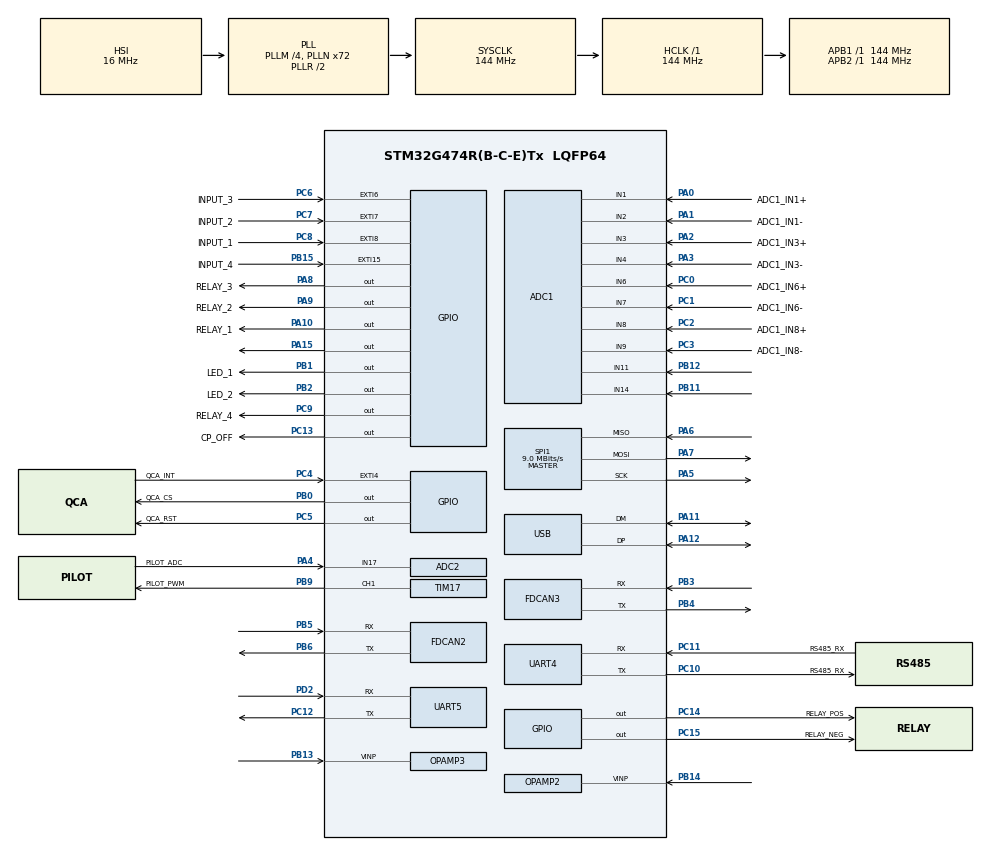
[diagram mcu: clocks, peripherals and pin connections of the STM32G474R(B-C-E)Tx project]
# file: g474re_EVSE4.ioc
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ADC1.Channel-26\#ChannelRegularConversion=ADC_CHANNEL_1
ADC1.Channel-27\#ChannelRegularConversion=ADC_CHANNEL_2
ADC1.Channel-28\#ChannelRegularConversion=ADC_CHANNEL_3
ADC1.Channel-29\#ChannelRegularConversion=ADC_CHANNEL_4
ADC1.Channel-30\#ChannelRegularConversion=ADC_CHANNEL_6
ADC1.Channel-31\#ChannelRegularConversion=ADC_CHANNEL_7
ADC1.Channel-32\#ChannelRegularConversion=ADC_CHANNEL_8
ADC1.Channel-33\#ChannelRegularConversion=ADC_CHANNEL_9
ADC1.Channel-34\#ChannelRegularConversion=ADC_CHANNEL_TEMPSENSOR_ADC1
ADC1.Channel-35\#ChannelRegularConversion=ADC_CHANNEL_VREFINT
ADC1.Channel-36\#ChannelRegularConversion=ADC_CHANNEL_TEMPSENSOR_ADC1
ADC1.Channel-37\#ChannelRegularConversion=ADC_CHANNEL_11
ADC1.Channel-38\#ChannelRegularConversion=ADC_CHANNEL_14
ADC1.ClockPrescaler=ADC_CLOCK_ASYNC_DIV256
ADC1.ContinuousConvMode=ENABLE
ADC1.DMAContinuousRequests=DISABLE
ADC1.EOCSelection=ADC_EOC_SEQ_CONV
ADC1.EnableRegularConversion=ENABLE
ADC1.NbrOfConversion=13
ADC1.NbrOfConversionFlag=1
ADC1.OffsetNumber-26\#ChannelRegularConversion=ADC_OFFSET_NONE
ADC1.OffsetNumber-27\#ChannelRegularConversion=ADC_OFFSET_NONE
ADC1.OffsetNumber-28\#ChannelRegularConversion=ADC_OFFSET_NONE
ADC1.OffsetNumber-29\#ChannelRegularConversion=ADC_OFFSET_NONE
ADC1.OffsetNumber-30\#ChannelRegularConversion=ADC_OFFSET_NONE
ADC1.OffsetNumber-31\#ChannelRegularConversion=ADC_OFFSET_NONE
ADC1.OffsetNumber-32\#ChannelRegularConversion=ADC_OFFSET_NONE
ADC1.OffsetNumber-33\#ChannelRegularConversion=ADC_OFFSET_NONE
ADC1.OffsetNumber-34\#ChannelRegularConversion=ADC_OFFSET_NONE
ADC1.OffsetNumber-35\#ChannelRegularConversion=ADC_OFFSET_NONE
ADC1.OffsetNumber-36\#ChannelRegularConversion=ADC_OFFSET_NONE
ADC1.OffsetNumber-37\#ChannelRegularConversion=ADC_OFFSET_NONE
ADC1.OffsetNumber-38\#ChannelRegularConversion=ADC_OFFSET_NONE
ADC1.Overrun=ADC_OVR_DATA_PRESERVED
ADC1.OversamplingMode=DISABLE
ADC1.Rank-26\#ChannelRegularConversion=1
ADC1.Rank-27\#ChannelRegularConversion=2
ADC1.Rank-28\#ChannelRegularConversion=3
ADC1.Rank-29\#ChannelRegularConversion=4
ADC1.Rank-30\#ChannelRegularConversion=5
ADC1.Rank-31\#ChannelRegularConversion=6
ADC1.Rank-32\#ChannelRegularConversion=7
ADC1.Rank-33\#ChannelRegularConversion=8
ADC1.Rank-34\#ChannelRegularConversion=9
ADC1.Rank-35\#ChannelRegularConversion=10
ADC1.Rank-36\#ChannelRegularConversion=11
ADC1.Rank-37\#ChannelRegularConversion=12
ADC1.Rank-38\#ChannelRegularConversion=13
ADC1.SamplingTime-26\#ChannelRegularConversion=ADC_SAMPLETIME_640CYCLES_5
ADC1.SamplingTime-27\#ChannelRegularConversion=ADC_SAMPLETIME_640CYCLES_5
ADC1.SamplingTime-28\#ChannelRegularConversion=ADC_SAMPLETIME_640CYCLES_5
ADC1.SamplingTime-29\#ChannelRegularConversion=ADC_SAMPLETIME_640CYCLES_5
ADC1.SamplingTime-30\#ChannelRegularConversion=ADC_SAMPLETIME_640CYCLES_5
ADC1.SamplingTime-31\#ChannelRegularConversion=ADC_SAMPLETIME_640CYCLES_5
ADC1.SamplingTime-32\#ChannelRegularConversion=ADC_SAMPLETIME_640CYCLES_5
ADC1.SamplingTime-33\#ChannelRegularConversion=ADC_SAMPLETIME_640CYCLES_5
ADC1.SamplingTime-34\#ChannelRegularConversion=ADC_SAMPLETIME_640CYCLES_5
ADC1.SamplingTime-35\#ChannelRegularConversion=ADC_SAMPLETIME_640CYCLES_5
ADC1.SamplingTime-36\#ChannelRegularConversion=ADC_SAMPLETIME_640CYCLES_5
ADC1.SamplingTime-37\#ChannelRegularConversion=ADC_SAMPLETIME_640CYCLES_5
ADC1.SamplingTime-38\#ChannelRegularConversion=ADC_SAMPLETIME_640CYCLES_5
ADC1.master=1
ADC2.Channel-0\#ChannelRegularConversion=ADC_CHANNEL_17
ADC2.Channel-1\#ChannelRegularConversion=ADC_CHANNEL_VOPAMP2
ADC2.Channel-2\#ChannelRegularConversion=ADC_CHANNEL_VOPAMP3_ADC2
ADC2.ClockPrescaler=ADC_CLOCK_ASYNC_DIV256
ADC2.ContinuousConvMode=ENABLE
ADC2.EOCSelection=ADC_EOC_SEQ_CONV
ADC2.NbrOfConversion=3
ADC2.NbrOfConversionFlag=1
ADC2.OffsetNumber-0\#ChannelRegularConversion=ADC_OFFSET_NONE
ADC2.OffsetNumber-1\#ChannelRegularConversion=ADC_OFFSET_NONE
ADC2.OffsetNumber-2\#ChannelRegularConversion=ADC_OFFSET_NONE
ADC2.OversamplingMode=DISABLE
ADC2.Rank-0\#ChannelRegularConversion=1
ADC2.Rank-1\#ChannelRegularConversion=2
ADC2.Rank-2\#ChannelRegularConversion=3
ADC2.SamplingTime-0\#ChannelRegularConversion=ADC_SAMPLETIME_640CYCLES_5
ADC2.SamplingTime-1\#ChannelRegularConversion=ADC_SAMPLETIME_640CYCLES_5
ADC2.SamplingTime-2\#ChannelRegularConversion=ADC_SAMPLETIME_640CYCLES_5
Dma.ADC1.0.Direction=DMA_PERIPH_TO_MEMORY
Dma.ADC1.0.EventEnable=DISABLE
Dma.ADC1.0.Instance=DMA1_Channel1
Dma.ADC1.0.MemDataAlignment=DMA_MDATAALIGN_WORD
Dma.ADC1.0.MemInc=DMA_MINC_ENABLE
Dma.ADC1.0.Mode=DMA_CIRCULAR
Dma.ADC1.0.PeriphDataAlignment=DMA_PDATAALIGN_WORD
Dma.ADC1.0.PeriphInc=DMA_PINC_DISABLE
Dma.ADC1.0.Polarity=HAL_DMAMUX_REQ_GEN_RISING
Dma.ADC1.0.Priority=DMA_PRIORITY_LOW
Dma.ADC1.0.RequestNumber=1
Dma.ADC1.0.SignalID=NONE
Dma.ADC1.0.SyncEnable=DISABLE
Dma.ADC1.0.SyncPolarity=HAL_DMAMUX_SYNC_NO_EVENT
Dma.ADC1.0.SyncRequestNumber=1
Dma.ADC1.0.SyncSignalID=NONE
Dma.ADC2.1.Direction=DMA_PERIPH_TO_MEMORY
Dma.ADC2.1.EventEnable=DISABLE
Dma.ADC2.1.Instance=DMA1_Channel2
Dma.ADC2.1.MemDataAlignment=DMA_MDATAALIGN_WORD
Dma.ADC2.1.MemInc=DMA_MINC_ENABLE
Dma.ADC2.1.Mode=DMA_CIRCULAR
Dma.ADC2.1.PeriphDataAlignment=DMA_PDATAALIGN_WORD
Dma.ADC2.1.PeriphInc=DMA_PINC_DISABLE
Dma.ADC2.1.Polarity=HAL_DMAMUX_REQ_GEN_RISING
Dma.ADC2.1.Priority=DMA_PRIORITY_LOW
Dma.ADC2.1.RequestNumber=1
Dma.ADC2.1.SignalID=NONE
Dma.ADC2.1.SyncEnable=DISABLE
Dma.ADC2.1.SyncPolarity=HAL_DMAMUX_SYNC_NO_EVENT
Dma.ADC2.1.SyncRequestNumber=1
Dma.ADC2.1.SyncSignalID=NONE
Dma.Request0=ADC1
Dma.Request1=ADC2
Dma.Request2=UART5_RX
Dma.Request3=UART5_TX
Dma.UART5_RX.2.Direction=DMA_PERIPH_TO_MEMORY
Dma.UART5_RX.2.EventEnable=DISABLE
Dma.UART5_RX.2.Instance=DMA1_Channel3
Dma.UART5_RX.2.MemDataAlignment=DMA_MDATAALIGN_BYTE
Dma.UART5_RX.2.MemInc=DMA_MINC_ENABLE
Dma.UART5_RX.2.Mode=DMA_CIRCULAR
Dma.UART5_RX.2.PeriphDataAlignment=DMA_PDATAALIGN_BYTE
Dma.UART5_RX.2.PeriphInc=DMA_PINC_DISABLE
Dma.UART5_RX.2.Polarity=HAL_DMAMUX_REQ_GEN_RISING
Dma.UART5_RX.2.Priority=DMA_PRIORITY_LOW
Dma.UART5_RX.2.RequestNumber=1
Dma.UART5_RX.2.SignalID=NONE
Dma.UART5_RX.2.SyncEnable=DISABLE
Dma.UART5_RX.2.SyncPolarity=HAL_DMAMUX_SYNC_NO_EVENT
Dma.UART5_RX.2.SyncRequestNumber=1
Dma.UART5_RX.2.SyncSignalID=NONE
Dma.UART5_TX.3.Direction=DMA_MEMORY_TO_PERIPH
Dma.UART5_TX.3.EventEnable=DISABLE
Dma.UART5_TX.3.Instance=DMA1_Channel4
Dma.UART5_TX.3.MemDataAlignment=DMA_MDATAALIGN_BYTE
Dma.UART5_TX.3.MemInc=DMA_MINC_ENABLE
Dma.UART5_TX.3.Mode=DMA_NORMAL
Dma.UART5_TX.3.PeriphDataAlignment=DMA_PDATAALIGN_BYTE
Dma.UART5_TX.3.PeriphInc=DMA_PINC_DISABLE
Dma.UART5_TX.3.Polarity=HAL_DMAMUX_REQ_GEN_RISING
Dma.UART5_TX.3.Priority=DMA_PRIORITY_LOW
Dma.UART5_TX.3.RequestNumber=1
Dma.UART5_TX.3.SignalID=NONE
Dma.UART5_TX.3.SyncEnable=DISABLE
Dma.UART5_TX.3.SyncPolarity=HAL_DMAMUX_SYNC_NO_EVENT
Dma.UART5_TX.3.SyncRequestNumber=1
Dma.UART5_TX.3.SyncSignalID=NONE
FDCAN2.AutoRetransmission=DISABLE
FDCAN2.CalculateBaudRateNominal=125000
FDCAN2.CalculateTimeBitNominal=8000
FDCAN2.CalculateTimeQuantumNominal=125.0
FDCAN2.DataSyncJumpWidth=4
FDCAN2.DataTimeSeg1=5
FDCAN2.DataTimeSeg2=4
FDCAN2.ExtFiltersNbr=1
FDCAN2.FrameFormat=FDCAN_FRAME_FD_BRS
FDCAN2.NominalPrescaler=6
FDCAN2.NominalSyncJumpWidth=16
FDCAN2.NominalTimeSeg1=28
FDCAN2.NominalTimeSeg2=35
FDCAN2.ProtocolException=DISABLE
FDCAN2.StdFiltersNbr=1
FDCAN2.TransmitPause=ENABLE
FDCAN3.AutoRetransmission=DISABLE
FDCAN3.CalculateBaudRateNominal=125000
FDCAN3.CalculateTimeBitNominal=8000
FDCAN3.CalculateTimeQuantumNominal=125.0
FDCAN3.DataSyncJumpWidth=4
FDCAN3.DataTimeSeg2=4
FDCAN3.ExtFiltersNbr=1
FDCAN3.FrameFormat=FDCAN_FRAME_FD_BRS
FDCAN3.NominalPrescaler=6
FDCAN3.NominalSyncJumpWidth=16
FDCAN3.NominalTimeSeg1=28
FDCAN3.NominalTimeSeg2=35
FDCAN3.StdFiltersNbr=1
FDCAN3.TransmitPause=DISABLE
Mcu.Family=STM32G4
Mcu.Name=STM32G474R(B-C-E)Tx
Mcu.Package=LQFP64
NVIC.ADC1_2_IRQn=true\:0\:0\:false\:false\:true\:true\:true\:true
NVIC.DMA1_Channel1_IRQn=true\:0\:0\:false\:false\:true\:false\:true\:true
NVIC.DMA1_Channel2_IRQn=true\:0\:0\:false\:false\:true\:false\:true\:true
NVIC.DMA1_Channel3_IRQn=true\:0\:0\:false\:false\:true\:false\:true\:true
NVIC.DMA1_Channel4_IRQn=true\:0\:0\:false\:false\:true\:false\:true\:true
NVIC.EXTI4_IRQn=true\:0\:0\:false\:false\:true\:true\:true\:true
NVIC.FDCAN2_IT0_IRQn=true\:0\:0\:false\:false\:true\:true\:true\:true
NVIC.FDCAN3_IT0_IRQn=true\:0\:0\:false\:false\:true\:true\:true\:true
NVIC.PriorityGroup=NVIC_PRIORITYGROUP_4
NVIC.RNG_IRQn=true\:0\:0\:false\:false\:true\:true\:true\:true
NVIC.TIM2_IRQn=true\:0\:0\:false\:false\:true\:true\:true\:true
NVIC.UART5_IRQn=true\:0\:0\:false\:false\:true\:true\:true\:true
NVIC.USB_LP_IRQn=true\:0\:0\:false\:false\:true\:true\:true\:true
OPAMP2.PgaGain=OPAMP_PGA_GAIN_4_OR_MINUS_3
OPAMP2.PowerMode=OPAMP_POWERMODE_HIGHSPEED
OPAMP3.PgaGain=OPAMP_PGA_GAIN_4_OR_MINUS_3
OPAMP3.PowerMode=OPAMP_POWERMODE_HIGHSPEED
PA0.GPIO_Label=ADC1_IN1+
PA0.Mode=IN1-Single-Ended
PA0.Signal=ADC1_IN1
PA1.GPIO_Label=ADC1_IN1-
PA1.Mode=IN2-Single-Ended
PA1.Signal=ADC1_IN2
PA10.GPIO_Label=RELAY_1
PA10.PinState=GPIO_PIN_RESET
PA10.Signal=GPIO_Output
PA11.Mode=Device
PA11.Signal=USB_DM
PA12.Mode=Device
PA12.Signal=USB_DP
PA13.GPIO_Label=T_SWDIO
PA13.Mode=Serial_Wire
PA13.Signal=SYS_JTMS-SWDIO
PA14.GPIO_Label=T_SWCLK
PA14.Mode=Serial_Wire
PA14.Signal=SYS_JTCK-SWCLK
PA15.Signal=GPIO_Output
PA2.GPIO_Label=ADC1_IN3+
PA2.Mode=IN3-Single-Ended
PA2.Signal=ADC1_IN3
PA3.GPIO_Label=ADC1_IN3-
PA3.Mode=IN4-Single-Ended
PA3.Signal=ADC1_IN4
PA4.GPIO_Label=PILOT_ADC
PA4.Mode=IN17-Single-Ended
PA4.Signal=ADC2_IN17
PA5.Mode=Full_Duplex_Master
PA5.Signal=SPI1_SCK
PA6.Mode=Full_Duplex_Master
PA6.Signal=SPI1_MISO
PA7.Mode=Full_Duplex_Master
PA7.Signal=SPI1_MOSI
PA8.GPIO_Label=RELAY_3
PA8.PinState=GPIO_PIN_RESET
PA8.Signal=GPIO_Output
PA9.GPIO_Label=RELAY_2
PA9.PinState=GPIO_PIN_RESET
PA9.Signal=GPIO_Output
PB0.GPIO_Label=QCA_CS
PB0.Signal=GPIO_Output
PB1.GPIO_Label=LED_1
PB1.Signal=GPIO_Output
PB11.Mode=IN14-Single-Ended
PB11.Signal=ADC1_IN14
PB12.Mode=IN11-Single-Ended
PB12.Signal=ADC1_IN11
PB13.Mode=PGA_Internally_Connected
PB13.Signal=OPAMP3_VINP
PB14.Mode=PGA_Internally_Connected
PB14.Signal=OPAMP2_VINP
PB15.GPIO_Label=INPUT_4
PB15.Signal=GPXTI15
PB2.GPIO_Label=LED_2
PB2.Signal=GPIO_Output
PB3.Mode=FDCAN_Activate
PB3.Signal=FDCAN3_RX
PB4.Mode=FDCAN_Activate
PB4.Signal=FDCAN3_TX
PB5.Mode=FDCAN_Activate
PB5.Signal=FDCAN2_RX
PB6.Mode=FDCAN_Activate
PB6.Signal=FDCAN2_TX
PB9.GPIO_Label=PILOT_PWM
PB9.Signal=S_TIM17_CH1
PC0.GPIO_Label=ADC1_IN6+
PC0.Mode=IN6-Single-Ended
PC0.Signal=ADC1_IN6
PC1.GPIO_Label=ADC1_IN6-
PC1.Mode=IN7-Single-Ended
PC1.Signal=ADC1_IN7
PC10.GPIO_Label=RS485_RX
PC10.Mode=Asynchronous
PC10.Signal=UART4_TX
PC11.GPIO_Label=RS485_RX
PC11.Mode=Asynchronous
PC11.Signal=UART4_RX
PC12.Mode=Asynchronous
PC12.Signal=UART5_TX
PC13.GPIO_Label=CP_OFF
PC13.Signal=GPIO_Output
PC14-OSC32_IN.GPIO_Label=RELAY_POS
PC14-OSC32_IN.Signal=GPIO_Output
PC15-OSC32_OUT.GPIO_Label=RELAY_NEG
PC15-OSC32_OUT.Signal=GPIO_Output
PC2.GPIO_Label=ADC1_IN8+
PC2.Mode=IN8-Single-Ended
PC2.Signal=ADC1_IN8
PC3.GPIO_Label=ADC1_IN8-
PC3.Mode=IN9-Single-Ended
PC3.Signal=ADC1_IN9
PC4.GPIO_Label=QCA_INT
PC4.Signal=GPXTI4
PC5.GPIO_Label=QCA_RST
PC5.Signal=GPIO_Output
PC6.GPIO_Label=INPUT_3
PC6.Signal=GPXTI6
PC7.GPIO_Label=INPUT_2
PC7.Signal=GPXTI7
PC8.GPIO_Label=INPUT_1
PC8.Signal=GPXTI8
PC9.GPIO_Label=RELAY_4
PC9.PinState=GPIO_PIN_RESET
PC9.Signal=GPIO_Output
PD2.Mode=Asynchronous
PD2.Signal=UART5_RX
PF0-OSC_IN.Mode=HSE-External-Oscillator
PF0-OSC_IN.Signal=RCC_OSC_IN
PF1-OSC_OUT.Mode=HSE-External-Oscillator
PF1-OSC_OUT.Signal=RCC_OSC_OUT
ProjectManager.HeapSize=0x200
ProjectManager.StackSize=0x400
ProjectManager.TargetToolchain=STM32CubeIDE
RCC.ADC12Freq_Value=144000000
RCC.ADC345Freq_Value=144000000
RCC.AHBFreq_Value=144000000
RCC.APB1Freq_Value=144000000
RCC.APB1TimFreq_Value=144000000
RCC.APB2Freq_Value=144000000
RCC.APB2TimFreq_Value=144000000
RCC.CortexFreq_Value=144000000
RCC.EXTERNAL_CLOCK_VALUE=12288000
RCC.FDCANCLockSelection=RCC_FDCANCLKSOURCE_PLL
RCC.HCLKFreq_Value=144000000
RCC.HSE_VALUE=24000000
RCC.HSI48_VALUE=48000000
RCC.HSI_VALUE=16000000
RCC.LSE_VALUE=32768
RCC.PLLM=RCC_PLLM_DIV4
RCC.PLLN=72
RCC.PLLQ=RCC_PLLQ_DIV6
RCC.RTCClockSelection=RCC_RTCCLKSOURCE_LSE
RCC.SYSCLKFreq_VALUE=144000000
RCC.SYSCLKSource=RCC_SYSCLKSOURCE_PLLCLK
RCC.USBFreq_Value=48000000
RCC.VCOOutputFreq_Value=288000000
SH.S_TIM17_CH1.0=TIM17_CH1,PWM Generation1 CH1
SPI1.BaudRatePrescaler=SPI_BAUDRATEPRESCALER_16
SPI1.CLKPhase=SPI_PHASE_2EDGE
SPI1.CLKPolarity=SPI_POLARITY_HIGH
SPI1.CalculateBaudRate=9.0 MBits/s
SPI1.DataSize=SPI_DATASIZE_8BIT
SPI1.Direction=SPI_DIRECTION_2LINES
SPI1.Mode=SPI_MODE_MASTER
SPI1.VirtualType=VM_MASTER
TIM17.AutoReloadPreload=TIM_AUTORELOAD_PRELOAD_ENABLE
TIM17.Channel=TIM_CHANNEL_1
TIM17.PeriodNoDither=100-1
TIM17.Prescaler=1440-1
TIM2.AutoReloadPreload=TIM_AUTORELOAD_PRELOAD_ENABLE
TIM2.Dithering=Disable
TIM2.PeriodNoDither=1000-1
TIM2.Prescaler=144-1
TIM2.TIM_MasterOutputTrigger=TIM_TRGO_RESET
TIM2.TIM_MasterSlaveMode=TIM_MASTERSLAVEMODE_DISABLE
USB.Sof_enable=DISABLE
VP_ADC1_TempSens_Input.Mode=IN-TempSens
VP_ADC1_Vref_Input.Mode=IN-Vrefint
VP_ADC2_OPAMP_INTERNAL2.Mode=IN-OPAMP2
VP_ADC2_OPAMP_INTERNAL3.Mode=IN-OPAMP3
VP_RNG_VS_RNG.Mode=RNG_Activate
VP_SYS_VS_DBSignals.Mode=DisableDeadBatterySignals
VP_TIM17_VS_ClockSourceINT.Mode=Enable_Timer
VP_TIM2_VS_ClockSourceINT.Mode=Internal
board=NUCLEO-G474RE

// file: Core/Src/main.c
/* USER CODE BEGIN Header */
/**
  ******************************************************************************
  * @file           : main.c
  * @brief          : Main program body
  ******************************************************************************
  * @attention
  *
  * Copyright (c) 2024 STMicroelectronics.
  * All rights reserved.
  *
  * This software is licensed under terms that can be found in the LICENSE file
  * in the root directory of this software component.
  * If no LICENSE file comes with this software, it is provided AS-IS.
  *
  ******************************************************************************
  */
/* USER CODE END Header */
#include "main.h"

/* USER CODE BEGIN Includes */
#include "ccs32_globals.h"
#include "usb_device.h"
/* USER CODE END Includes */

ADC_HandleTypeDef hadc1;
ADC_HandleTypeDef hadc2;
DMA_HandleTypeDef hdma_adc1;
DMA_HandleTypeDef hdma_adc2;

FDCAN_HandleTypeDef hfdcan2;
FDCAN_HandleTypeDef hfdcan3;

OPAMP_HandleTypeDef hopamp2;
OPAMP_HandleTypeDef hopamp3;

RNG_HandleTypeDef hrng;

SPI_HandleTypeDef hspi1;

TIM_HandleTypeDef htim2;
TIM_HandleTypeDef htim17;

UART_HandleTypeDef huart4;
UART_HandleTypeDef huart5;
DMA_HandleTypeDef hdma_uart5_rx;
DMA_HandleTypeDef hdma_uart5_tx;

PCD_HandleTypeDef hpcd_USB_FS;

/* USER CODE BEGIN PV */
uint32_t value_adc;
/* USER CODE END PV */

void SystemClock_Config(void);
static void MX_GPIO_Init(void);
static void MX_DMA_Init(void);
static void MX_ADC1_Init(void);
static void MX_SPI1_Init(void);
static void MX_FDCAN3_Init(void);
static void MX_TIM17_Init(void);
static void MX_UART4_Init(void);
static void MX_FDCAN2_Init(void);
static void MX_ADC2_Init(void);
static void MX_TIM2_Init(void);
static void MX_UART5_Init(void);
static void MX_RNG_Init(void);
static void MX_USB_PCD_Init(void);
static void MX_OPAMP2_Init(void);
static void MX_OPAMP3_Init(void);

int main(void)
{

  /* MCU Configuration--------------------------------------------------------*/

  /* Reset of all peripherals, Initializes the Flash interface and the Systick. */
  HAL_Init();

  /* Configure the system clock */
  SystemClock_Config();

  /* Initialize all configured peripherals */
  MX_GPIO_Init();
  MX_DMA_Init();
  MX_ADC1_Init();
  MX_SPI1_Init();
  MX_FDCAN3_Init();
  MX_TIM17_Init();
  MX_UART4_Init();
  MX_FDCAN2_Init();
  MX_ADC2_Init();
  MX_TIM2_Init();
  MX_UART5_Init();
  MX_RNG_Init();
  MX_USB_PCD_Init();
  MX_OPAMP2_Init();
  MX_OPAMP3_Init();
  /* USER CODE BEGIN 2 */
 // HAL_DAC_Start(&hdac1,DAC_CHANNEL_2);
 // HAL_ADCEx_Calibration_Start(&hadc1, ADC_SINGLE_ENDED);
 // HAL_ADC_Start_DMA(&hadc1,(uint32_t*)&value_adc,1);
  MX_USB_DEVICE_Init();
  /* USER CODE END 2 */

  /* Infinite loop */
  /* USER CODE BEGIN WHILE */

  while (1)
  {

//	  while(1){
//		  HAL_ADC_Start_DMA(&hadc1, &AD_RES, 1);
//		  HAL_Delay(1);
//	  }
    /* USER CODE END WHILE */

    /* USER CODE BEGIN 3 */

	  app_init();

	  //app_run();
  }
  /* USER CODE END 3 */
}

void SystemClock_Config(void)
{
  RCC_OscInitTypeDef RCC_OscInitStruct = {0};
  RCC_ClkInitTypeDef RCC_ClkInitStruct = {0};

  /** Configure the main internal regulator output voltage
  */
  HAL_PWREx_ControlVoltageScaling(PWR_REGULATOR_VOLTAGE_SCALE1);

  /** Initializes the RCC Oscillators according to the specified parameters
  * in the RCC_OscInitTypeDef structure.
  */
  RCC_OscInitStruct.OscillatorType = RCC_OSCILLATORTYPE_HSI;
  RCC_OscInitStruct.HSIState = RCC_HSI_ON;
  RCC_OscInitStruct.HSICalibrationValue = RCC_HSICALIBRATION_DEFAULT;
  RCC_OscInitStruct.PLL.PLLState = RCC_PLL_ON;
  RCC_OscInitStruct.PLL.PLLSource = RCC_PLLSOURCE_HSI;
  RCC_OscInitStruct.PLL.PLLM = RCC_PLLM_DIV4;
  RCC_OscInitStruct.PLL.PLLN = 72;
  RCC_OscInitStruct.PLL.PLLP = RCC_PLLP_DIV2;
  RCC_OscInitStruct.PLL.PLLQ = RCC_PLLQ_DIV6;
  RCC_OscInitStruct.PLL.PLLR = RCC_PLLR_DIV2;
  if (HAL_RCC_OscConfig(&RCC_OscInitStruct) != HAL_OK)
  {
    Error_Handler();
  }

  /** Initializes the CPU, AHB and APB buses clocks
  */
  RCC_ClkInitStruct.ClockType = RCC_CLOCKTYPE_HCLK|RCC_CLOCKTYPE_SYSCLK
                              |RCC_CLOCKTYPE_PCLK1|RCC_CLOCKTYPE_PCLK2;
  RCC_ClkInitStruct.SYSCLKSource = RCC_SYSCLKSOURCE_PLLCLK;
  RCC_ClkInitStruct.AHBCLKDivider = RCC_SYSCLK_DIV1;
  RCC_ClkInitStruct.APB1CLKDivider = RCC_HCLK_DIV1;
  RCC_ClkInitStruct.APB2CLKDivider = RCC_HCLK_DIV1;

  if (HAL_RCC_ClockConfig(&RCC_ClkInitStruct, FLASH_LATENCY_4) != HAL_OK)
  {
    Error_Handler();
  }
}

static void MX_ADC1_Init(void)
{

  ADC_MultiModeTypeDef multimode = {0};
  ADC_ChannelConfTypeDef sConfig = {0};

  /** Common config
  */
  hadc1.Instance = ADC1;
  hadc1.Init.ClockPrescaler = ADC_CLOCK_ASYNC_DIV256;
  hadc1.Init.Resolution = ADC_RESOLUTION_12B;
  hadc1.Init.DataAlign = ADC_DATAALIGN_RIGHT;
  hadc1.Init.GainCompensation = 0;
  hadc1.Init.ScanConvMode = ADC_SCAN_ENABLE;
  hadc1.Init.EOCSelection = ADC_EOC_SEQ_CONV;
  hadc1.Init.LowPowerAutoWait = DISABLE;
  hadc1.Init.ContinuousConvMode = ENABLE;
  hadc1.Init.NbrOfConversion = 13;
  hadc1.Init.DiscontinuousConvMode = DISABLE;
  hadc1.Init.ExternalTrigConv = ADC_SOFTWARE_START;
  hadc1.Init.ExternalTrigConvEdge = ADC_EXTERNALTRIGCONVEDGE_NONE;
  hadc1.Init.DMAContinuousRequests = DISABLE;
  hadc1.Init.Overrun = ADC_OVR_DATA_PRESERVED;
  hadc1.Init.OversamplingMode = DISABLE;
  if (HAL_ADC_Init(&hadc1) != HAL_OK)
  {
    Error_Handler();
  }

  /** Configure the ADC multi-mode
  */
  multimode.Mode = ADC_MODE_INDEPENDENT;
  if (HAL_ADCEx_MultiModeConfigChannel(&hadc1, &multimode) != HAL_OK)
  {
    Error_Handler();
  }

  /** Configure Regular Channel
  */
  sConfig.Channel = ADC_CHANNEL_1;
  sConfig.Rank = ADC_REGULAR_RANK_1;
  sConfig.SamplingTime = ADC_SAMPLETIME_640CYCLES_5;
  sConfig.SingleDiff = ADC_SINGLE_ENDED;
  sConfig.OffsetNumber = ADC_OFFSET_NONE;
  sConfig.Offset = 0;
  if (HAL_ADC_ConfigChannel(&hadc1, &sConfig) != HAL_OK)
  {
    Error_Handler();
  }

  /** Configure Regular Channel
  */
  sConfig.Channel = ADC_CHANNEL_2;
  sConfig.Rank = ADC_REGULAR_RANK_2;
  if (HAL_ADC_ConfigChannel(&hadc1, &sConfig) != HAL_OK)
  {
    Error_Handler();
  }

  /** Configure Regular Channel
  */
  sConfig.Channel = ADC_CHANNEL_3;
  sConfig.Rank = ADC_REGULAR_RANK_3;
  if (HAL_ADC_ConfigChannel(&hadc1, &sConfig) != HAL_OK)
  {
    Error_Handler();
  }

  /** Configure Regular Channel
  */
  sConfig.Channel = ADC_CHANNEL_4;
  sConfig.Rank = ADC_REGULAR_RANK_4;
  if (HAL_ADC_ConfigChannel(&hadc1, &sConfig) != HAL_OK)
  {
    Error_Handler();
  }

  /** Configure Regular Channel
  */
  sConfig.Channel = ADC_CHANNEL_6;
  sConfig.Rank = ADC_REGULAR_RANK_5;
  if (HAL_ADC_ConfigChannel(&hadc1, &sConfig) != HAL_OK)
  {
    Error_Handler();
  }

  /** Configure Regular Channel
  */
  sConfig.Channel = ADC_CHANNEL_7;
  sConfig.Rank = ADC_REGULAR_RANK_6;
  if (HAL_ADC_ConfigChannel(&hadc1, &sConfig) != HAL_OK)
  {
    Error_Handler();
  }

  /** Configure Regular Channel
  */
  sConfig.Channel = ADC_CHANNEL_8;
  sConfig.Rank = ADC_REGULAR_RANK_7;
  if (HAL_ADC_ConfigChannel(&hadc1, &sConfig) != HAL_OK)
  {
    Error_Handler();
  }

  /** Configure Regular Channel
  */
  sConfig.Channel = ADC_CHANNEL_9;
  sConfig.Rank = ADC_REGULAR_RANK_8;
  if (HAL_ADC_ConfigChannel(&hadc1, &sConfig) != HAL_OK)
  {
    Error_Handler();
  }

  /** Configure Regular Channel
  */
  sConfig.Channel = ADC_CHANNEL_TEMPSENSOR_ADC1;
  sConfig.Rank = ADC_REGULAR_RANK_9;
  if (HAL_ADC_ConfigChannel(&hadc1, &sConfig) != HAL_OK)
  {
    Error_Handler();
  }

  /** Configure Regular Channel
  */
  sConfig.Channel = ADC_CHANNEL_VREFINT;
  sConfig.Rank = ADC_REGULAR_RANK_10;
  if (HAL_ADC_ConfigChannel(&hadc1, &sConfig) != HAL_OK)
  {
    Error_Handler();
  }

  /** Configure Regular Channel
  */
  sConfig.Channel = ADC_CHANNEL_TEMPSENSOR_ADC1;
  sConfig.Rank = ADC_REGULAR_RANK_11;
  if (HAL_ADC_ConfigChannel(&hadc1, &sConfig) != HAL_OK)
  {
    Error_Handler();
  }

  /** Configure Regular Channel
  */
  sConfig.Channel = ADC_CHANNEL_11;
  sConfig.Rank = ADC_REGULAR_RANK_12;
  if (HAL_ADC_ConfigChannel(&hadc1, &sConfig) != HAL_OK)
  {
    Error_Handler();
  }

  /** Configure Regular Channel
  */
  sConfig.Channel = ADC_CHANNEL_14;
  sConfig.Rank = ADC_REGULAR_RANK_13;
  if (HAL_ADC_ConfigChannel(&hadc1, &sConfig) != HAL_OK)
  {
    Error_Handler();
  }

}

static void MX_ADC2_Init(void)
{

  ADC_ChannelConfTypeDef sConfig = {0};

  /** Common config
  */
  hadc2.Instance = ADC2;
  hadc2.Init.ClockPrescaler = ADC_CLOCK_ASYNC_DIV256;
  hadc2.Init.Resolution = ADC_RESOLUTION_12B;
  hadc2.Init.DataAlign = ADC_DATAALIGN_RIGHT;
  hadc2.Init.GainCompensation = 0;
  hadc2.Init.ScanConvMode = ADC_SCAN_ENABLE;
  hadc2.Init.EOCSelection = ADC_EOC_SEQ_CONV;
  hadc2.Init.LowPowerAutoWait = DISABLE;
  hadc2.Init.ContinuousConvMode = ENABLE;
  hadc2.Init.NbrOfConversion = 3;
  hadc2.Init.DiscontinuousConvMode = DISABLE;
  hadc2.Init.ExternalTrigConv = ADC_SOFTWARE_START;
  hadc2.Init.ExternalTrigConvEdge = ADC_EXTERNALTRIGCONVEDGE_NONE;
  hadc2.Init.DMAContinuousRequests = DISABLE;
  hadc2.Init.Overrun = ADC_OVR_DATA_PRESERVED;
  hadc2.Init.OversamplingMode = DISABLE;
  if (HAL_ADC_Init(&hadc2) != HAL_OK)
  {
    Error_Handler();
  }

  /** Configure Regular Channel
  */
  sConfig.Channel = ADC_CHANNEL_17;
  sConfig.Rank = ADC_REGULAR_RANK_1;
  sConfig.SamplingTime = ADC_SAMPLETIME_640CYCLES_5;
  sConfig.SingleDiff = ADC_SINGLE_ENDED;
  sConfig.OffsetNumber = ADC_OFFSET_NONE;
  sConfig.Offset = 0;
  if (HAL_ADC_ConfigChannel(&hadc2, &sConfig) != HAL_OK)
  {
    Error_Handler();
  }

  /** Configure Regular Channel
  */
  sConfig.Channel = ADC_CHANNEL_VOPAMP2;
  sConfig.Rank = ADC_REGULAR_RANK_2;
  if (HAL_ADC_ConfigChannel(&hadc2, &sConfig) != HAL_OK)
  {
    Error_Handler();
  }

  /** Configure Regular Channel
  */
  sConfig.Channel = ADC_CHANNEL_VOPAMP3_ADC2;
  sConfig.Rank = ADC_REGULAR_RANK_3;
  if (HAL_ADC_ConfigChannel(&hadc2, &sConfig) != HAL_OK)
  {
    Error_Handler();
  }

}

static void MX_FDCAN2_Init(void)
{

  hfdcan2.Instance = FDCAN2;
  hfdcan2.Init.ClockDivider = FDCAN_CLOCK_DIV1;
  hfdcan2.Init.FrameFormat = FDCAN_FRAME_FD_BRS;
  hfdcan2.Init.Mode = FDCAN_MODE_NORMAL;
  hfdcan2.Init.AutoRetransmission = DISABLE;
  hfdcan2.Init.TransmitPause = ENABLE;
  hfdcan2.Init.ProtocolException = DISABLE;
  hfdcan2.Init.NominalPrescaler = 6;
  hfdcan2.Init.NominalSyncJumpWidth = 16;
  hfdcan2.Init.NominalTimeSeg1 = 28;
  hfdcan2.Init.NominalTimeSeg2 = 35;
  hfdcan2.Init.DataPrescaler = 1;
  hfdcan2.Init.DataSyncJumpWidth = 4;
  hfdcan2.Init.DataTimeSeg1 = 5;
  hfdcan2.Init.DataTimeSeg2 = 4;
  hfdcan2.Init.StdFiltersNbr = 1;
  hfdcan2.Init.ExtFiltersNbr = 1;
  hfdcan2.Init.TxFifoQueueMode = FDCAN_TX_FIFO_OPERATION;
  if (HAL_FDCAN_Init(&hfdcan2) != HAL_OK)
  {
    Error_Handler();
  }

}

static void MX_FDCAN3_Init(void)
{

  hfdcan3.Instance = FDCAN3;
  hfdcan3.Init.ClockDivider = FDCAN_CLOCK_DIV1;
  hfdcan3.Init.FrameFormat = FDCAN_FRAME_FD_BRS;
  hfdcan3.Init.Mode = FDCAN_MODE_NORMAL;
  hfdcan3.Init.AutoRetransmission = DISABLE;
  hfdcan3.Init.TransmitPause = DISABLE;
  hfdcan3.Init.ProtocolException = DISABLE;
  hfdcan3.Init.NominalPrescaler = 6;
  hfdcan3.Init.NominalSyncJumpWidth = 16;
  hfdcan3.Init.NominalTimeSeg1 = 28;
  hfdcan3.Init.NominalTimeSeg2 = 35;
  hfdcan3.Init.DataPrescaler = 1;
  hfdcan3.Init.DataSyncJumpWidth = 4;
  hfdcan3.Init.DataTimeSeg1 = 1;
  hfdcan3.Init.DataTimeSeg2 = 4;
  hfdcan3.Init.StdFiltersNbr = 1;
  hfdcan3.Init.ExtFiltersNbr = 1;
  hfdcan3.Init.TxFifoQueueMode = FDCAN_TX_FIFO_OPERATION;
  if (HAL_FDCAN_Init(&hfdcan3) != HAL_OK)
  {
    Error_Handler();
  }

}

static void MX_OPAMP2_Init(void)
{

  hopamp2.Instance = OPAMP2;
  hopamp2.Init.PowerMode = OPAMP_POWERMODE_HIGHSPEED;
  hopamp2.Init.Mode = OPAMP_PGA_MODE;
  hopamp2.Init.NonInvertingInput = OPAMP_NONINVERTINGINPUT_IO1;
  hopamp2.Init.InternalOutput = ENABLE;
  hopamp2.Init.TimerControlledMuxmode = OPAMP_TIMERCONTROLLEDMUXMODE_DISABLE;
  hopamp2.Init.PgaConnect = OPAMP_PGA_CONNECT_INVERTINGINPUT_NO;
  hopamp2.Init.PgaGain = OPAMP_PGA_GAIN_4_OR_MINUS_3;
  hopamp2.Init.UserTrimming = OPAMP_TRIMMING_FACTORY;
  if (HAL_OPAMP_Init(&hopamp2) != HAL_OK)
  {
    Error_Handler();
  }

}

static void MX_OPAMP3_Init(void)
{

  hopamp3.Instance = OPAMP3;
  hopamp3.Init.PowerMode = OPAMP_POWERMODE_HIGHSPEED;
  hopamp3.Init.Mode = OPAMP_PGA_MODE;
  hopamp3.Init.NonInvertingInput = OPAMP_NONINVERTINGINPUT_IO1;
  hopamp3.Init.InternalOutput = ENABLE;
  hopamp3.Init.TimerControlledMuxmode = OPAMP_TIMERCONTROLLEDMUXMODE_DISABLE;
  hopamp3.Init.PgaConnect = OPAMP_PGA_CONNECT_INVERTINGINPUT_NO;
  hopamp3.Init.PgaGain = OPAMP_PGA_GAIN_4_OR_MINUS_3;
  hopamp3.Init.UserTrimming = OPAMP_TRIMMING_FACTORY;
  if (HAL_OPAMP_Init(&hopamp3) != HAL_OK)
  {
    Error_Handler();
  }

}

static void MX_RNG_Init(void)
{

  hrng.Instance = RNG;
  hrng.Init.ClockErrorDetection = RNG_CED_ENABLE;
  if (HAL_RNG_Init(&hrng) != HAL_OK)
  {
    Error_Handler();
  }

}

static void MX_SPI1_Init(void)
{

  /* SPI1 parameter configuration*/
  hspi1.Instance = SPI1;
  hspi1.Init.Mode = SPI_MODE_MASTER;
  hspi1.Init.Direction = SPI_DIRECTION_2LINES;
  hspi1.Init.DataSize = SPI_DATASIZE_8BIT;
  hspi1.Init.CLKPolarity = SPI_POLARITY_HIGH;
  hspi1.Init.CLKPhase = SPI_PHASE_2EDGE;
  hspi1.Init.NSS = SPI_NSS_SOFT;
  hspi1.Init.BaudRatePrescaler = SPI_BAUDRATEPRESCALER_16;
  hspi1.Init.FirstBit = SPI_FIRSTBIT_MSB;
  hspi1.Init.TIMode = SPI_TIMODE_DISABLE;
  hspi1.Init.CRCCalculation = SPI_CRCCALCULATION_DISABLE;
  hspi1.Init.CRCPolynomial = 7;
  hspi1.Init.CRCLength = SPI_CRC_LENGTH_DATASIZE;
  hspi1.Init.NSSPMode = SPI_NSS_PULSE_DISABLE;
  if (HAL_SPI_Init(&hspi1) != HAL_OK)
  {
    Error_Handler();
  }

}

static void MX_TIM2_Init(void)
{

  TIM_ClockConfigTypeDef sClockSourceConfig = {0};
  TIM_MasterConfigTypeDef sMasterConfig = {0};

  htim2.Instance = TIM2;
  htim2.Init.Prescaler = 144-1;
  htim2.Init.CounterMode = TIM_COUNTERMODE_UP;
  htim2.Init.Period = 999;
  htim2.Init.ClockDivision = TIM_CLOCKDIVISION_DIV1;
  htim2.Init.AutoReloadPreload = TIM_AUTORELOAD_PRELOAD_ENABLE;
  if (HAL_TIM_Base_Init(&htim2) != HAL_OK)
  {
    Error_Handler();
  }
  sClockSourceConfig.ClockSource = TIM_CLOCKSOURCE_INTERNAL;
  if (HAL_TIM_ConfigClockSource(&htim2, &sClockSourceConfig) != HAL_OK)
  {
    Error_Handler();
  }
  sMasterConfig.MasterOutputTrigger = TIM_TRGO_RESET;
  sMasterConfig.MasterSlaveMode = TIM_MASTERSLAVEMODE_DISABLE;
  if (HAL_TIMEx_MasterConfigSynchronization(&htim2, &sMasterConfig) != HAL_OK)
  {
    Error_Handler();
  }

}

static void MX_TIM17_Init(void)
{

  TIM_OC_InitTypeDef sConfigOC = {0};
  TIM_BreakDeadTimeConfigTypeDef sBreakDeadTimeConfig = {0};

  htim17.Instance = TIM17;
  htim17.Init.Prescaler = 1440-1;
  htim17.Init.CounterMode = TIM_COUNTERMODE_UP;
  htim17.Init.Period = 99;
  htim17.Init.ClockDivision = TIM_CLOCKDIVISION_DIV1;
  htim17.Init.RepetitionCounter = 0;
  htim17.Init.AutoReloadPreload = TIM_AUTORELOAD_PRELOAD_ENABLE;
  if (HAL_TIM_Base_Init(&htim17) != HAL_OK)
  {
    Error_Handler();
  }
  if (HAL_TIM_PWM_Init(&htim17) != HAL_OK)
  {
    Error_Handler();
  }
  sConfigOC.OCMode = TIM_OCMODE_PWM1;
  sConfigOC.Pulse = 0;
  sConfigOC.OCPolarity = TIM_OCPOLARITY_HIGH;
  sConfigOC.OCNPolarity = TIM_OCNPOLARITY_HIGH;
  sConfigOC.OCFastMode = TIM_OCFAST_DISABLE;
  sConfigOC.OCIdleState = TIM_OCIDLESTATE_RESET;
  sConfigOC.OCNIdleState = TIM_OCNIDLESTATE_RESET;
  if (HAL_TIM_PWM_ConfigChannel(&htim17, &sConfigOC, TIM_CHANNEL_1) != HAL_OK)
  {
    Error_Handler();
  }
  sBreakDeadTimeConfig.OffStateRunMode = TIM_OSSR_DISABLE;
  sBreakDeadTimeConfig.OffStateIDLEMode = TIM_OSSI_DISABLE;
  sBreakDeadTimeConfig.LockLevel = TIM_LOCKLEVEL_OFF;
  sBreakDeadTimeConfig.DeadTime = 0;
  sBreakDeadTimeConfig.BreakState = TIM_BREAK_DISABLE;
  sBreakDeadTimeConfig.BreakPolarity = TIM_BREAKPOLARITY_HIGH;
  sBreakDeadTimeConfig.BreakFilter = 0;
  sBreakDeadTimeConfig.AutomaticOutput = TIM_AUTOMATICOUTPUT_DISABLE;
  if (HAL_TIMEx_ConfigBreakDeadTime(&htim17, &sBreakDeadTimeConfig) != HAL_OK)
  {
    Error_Handler();
  }
  HAL_TIM_MspPostInit(&htim17);

}

static void MX_UART4_Init(void)
{

  huart4.Instance = UART4;
  huart4.Init.BaudRate = 115200;
  huart4.Init.WordLength = UART_WORDLENGTH_8B;
  huart4.Init.StopBits = UART_STOPBITS_1;
  huart4.Init.Parity = UART_PARITY_NONE;
  huart4.Init.Mode = UART_MODE_TX_RX;
  huart4.Init.HwFlowCtl = UART_HWCONTROL_NONE;
  huart4.Init.OverSampling = UART_OVERSAMPLING_16;
  huart4.Init.OneBitSampling = UART_ONE_BIT_SAMPLE_DISABLE;
  huart4.Init.ClockPrescaler = UART_PRESCALER_DIV1;
  huart4.AdvancedInit.AdvFeatureInit = UART_ADVFEATURE_NO_INIT;
  if (HAL_UART_Init(&huart4) != HAL_OK)
  {
    Error_Handler();
  }
  if (HAL_UARTEx_SetTxFifoThreshold(&huart4, UART_TXFIFO_THRESHOLD_1_8) != HAL_OK)
  {
    Error_Handler();
  }
  if (HAL_UARTEx_SetRxFifoThreshold(&huart4, UART_RXFIFO_THRESHOLD_1_8) != HAL_OK)
  {
    Error_Handler();
  }
  if (HAL_UARTEx_DisableFifoMode(&huart4) != HAL_OK)
  {
    Error_Handler();
  }

}

static void MX_UART5_Init(void)
{

  huart5.Instance = UART5;
  huart5.Init.BaudRate = 115200;
  huart5.Init.WordLength = UART_WORDLENGTH_8B;
  huart5.Init.StopBits = UART_STOPBITS_1;
  huart5.Init.Parity = UART_PARITY_NONE;
  huart5.Init.Mode = UART_MODE_TX_RX;
  huart5.Init.HwFlowCtl = UART_HWCONTROL_NONE;
  huart5.Init.OverSampling = UART_OVERSAMPLING_16;
  huart5.Init.OneBitSampling = UART_ONE_BIT_SAMPLE_DISABLE;
  huart5.Init.ClockPrescaler = UART_PRESCALER_DIV1;
  huart5.AdvancedInit.AdvFeatureInit = UART_ADVFEATURE_NO_INIT;
  if (HAL_UART_Init(&huart5) != HAL_OK)
  {
    Error_Handler();
  }
  if (HAL_UARTEx_SetTxFifoThreshold(&huart5, UART_TXFIFO_THRESHOLD_1_8) != HAL_OK)
  {
    Error_Handler();
  }
  if (HAL_UARTEx_SetRxFifoThreshold(&huart5, UART_RXFIFO_THRESHOLD_1_8) != HAL_OK)
  {
    Error_Handler();
  }
  if (HAL_UARTEx_DisableFifoMode(&huart5) != HAL_OK)
  {
    Error_Handler();
  }

}

static void MX_USB_PCD_Init(void)
{

  hpcd_USB_FS.Instance = USB;
  hpcd_USB_FS.Init.dev_endpoints = 8;
  hpcd_USB_FS.Init.speed = PCD_SPEED_FULL;
  hpcd_USB_FS.Init.phy_itface = PCD_PHY_EMBEDDED;
  hpcd_USB_FS.Init.Sof_enable = DISABLE;
  hpcd_USB_FS.Init.low_power_enable = DISABLE;
  hpcd_USB_FS.Init.lpm_enable = DISABLE;
  hpcd_USB_FS.Init.battery_charging_enable = DISABLE;
  if (HAL_PCD_Init(&hpcd_USB_FS) != HAL_OK)
  {
    Error_Handler();
  }

}

static void MX_DMA_Init(void)
{

  /* DMA controller clock enable */
  __HAL_RCC_DMAMUX1_CLK_ENABLE();
  __HAL_RCC_DMA1_CLK_ENABLE();

  /* DMA interrupt init */
  /* DMA1_Channel1_IRQn interrupt configuration */
  HAL_NVIC_SetPriority(DMA1_Channel1_IRQn, 0, 0);
  HAL_NVIC_EnableIRQ(DMA1_Channel1_IRQn);
  /* DMA1_Channel2_IRQn interrupt configuration */
  HAL_NVIC_SetPriority(DMA1_Channel2_IRQn, 0, 0);
  HAL_NVIC_EnableIRQ(DMA1_Channel2_IRQn);
  /* DMA1_Channel3_IRQn interrupt configuration */
  HAL_NVIC_SetPriority(DMA1_Channel3_IRQn, 0, 0);
  HAL_NVIC_EnableIRQ(DMA1_Channel3_IRQn);
  /* DMA1_Channel4_IRQn interrupt configuration */
  HAL_NVIC_SetPriority(DMA1_Channel4_IRQn, 0, 0);
  HAL_NVIC_EnableIRQ(DMA1_Channel4_IRQn);

}

static void MX_GPIO_Init(void)
{
  GPIO_InitTypeDef GPIO_InitStruct = {0};

  /* GPIO Ports Clock Enable */
  __HAL_RCC_GPIOC_CLK_ENABLE();
  __HAL_RCC_GPIOF_CLK_ENABLE();
  __HAL_RCC_GPIOA_CLK_ENABLE();
  __HAL_RCC_GPIOB_CLK_ENABLE();
  __HAL_RCC_GPIOD_CLK_ENABLE();

  /*Configure GPIO pin Output Level */
  HAL_GPIO_WritePin(GPIOC, CP_OFF_Pin|RELAY_POS_Pin|RELAY_NEG_Pin|QCA_RST_Pin
                          |RELAY_4_Pin, GPIO_PIN_RESET);

  /*Configure GPIO pin Output Level */
  HAL_GPIO_WritePin(GPIOB, QCA_CS_Pin|LED_1_Pin|LED_2_Pin, GPIO_PIN_RESET);

  /*Configure GPIO pin Output Level */
  HAL_GPIO_WritePin(GPIOA, RELAY_3_Pin|RELAY_2_Pin|RELAY_1_Pin|GPIO_PIN_15, GPIO_PIN_RESET);

  /*Configure GPIO pins : CP_OFF_Pin RELAY_POS_Pin RELAY_NEG_Pin QCA_RST_Pin
                           RELAY_4_Pin */
  GPIO_InitStruct.Pin = CP_OFF_Pin|RELAY_POS_Pin|RELAY_NEG_Pin|QCA_RST_Pin
                          |RELAY_4_Pin;
  GPIO_InitStruct.Mode = GPIO_MODE_OUTPUT_PP;
  GPIO_InitStruct.Pull = GPIO_NOPULL;
  GPIO_InitStruct.Speed = GPIO_SPEED_FREQ_LOW;
  HAL_GPIO_Init(GPIOC, &GPIO_InitStruct);

  /*Configure GPIO pins : QCA_INT_Pin INPUT_3_Pin INPUT_2_Pin INPUT_1_Pin */
  GPIO_InitStruct.Pin = QCA_INT_Pin|INPUT_3_Pin|INPUT_2_Pin|INPUT_1_Pin;
  GPIO_InitStruct.Mode = GPIO_MODE_IT_RISING;
  GPIO_InitStruct.Pull = GPIO_NOPULL;
  HAL_GPIO_Init(GPIOC, &GPIO_InitStruct);

  /*Configure GPIO pins : QCA_CS_Pin LED_1_Pin LED_2_Pin */
  GPIO_InitStruct.Pin = QCA_CS_Pin|LED_1_Pin|LED_2_Pin;
  GPIO_InitStruct.Mode = GPIO_MODE_OUTPUT_PP;
  GPIO_InitStruct.Pull = GPIO_NOPULL;
  GPIO_InitStruct.Speed = GPIO_SPEED_FREQ_LOW;
  HAL_GPIO_Init(GPIOB, &GPIO_InitStruct);

  /*Configure GPIO pin : INPUT_4_Pin */
  GPIO_InitStruct.Pin = INPUT_4_Pin;
  GPIO_InitStruct.Mode = GPIO_MODE_IT_RISING;
  GPIO_InitStruct.Pull = GPIO_NOPULL;
  HAL_GPIO_Init(INPUT_4_GPIO_Port, &GPIO_InitStruct);

  /*Configure GPIO pins : RELAY_3_Pin RELAY_2_Pin RELAY_1_Pin PA15 */
  GPIO_InitStruct.Pin = RELAY_3_Pin|RELAY_2_Pin|RELAY_1_Pin|GPIO_PIN_15;
  GPIO_InitStruct.Mode = GPIO_MODE_OUTPUT_PP;
  GPIO_InitStruct.Pull = GPIO_NOPULL;
  GPIO_InitStruct.Speed = GPIO_SPEED_FREQ_LOW;
  HAL_GPIO_Init(GPIOA, &GPIO_InitStruct);

  /* EXTI interrupt init*/
  HAL_NVIC_SetPriority(EXTI4_IRQn, 0, 0);
  HAL_NVIC_EnableIRQ(EXTI4_IRQn);

}

void Error_Handler(void)
{
  __disable_irq();
  while (1)
  {
  }
}
